# DSC28034 register map
Vendor: Beijing Haawking Technology Co.,Ltd.; File version: 1.0
Registers are 32-bit, read-write, reset 0x0 unless marked. A register's access mark holds for its fields unless they carry their own. Offsets are from the block's base; [hi:lo] are bit positions; {n}, {i} and the like mark numbered series; 'fields as' and 'values as' point back to an identical list.

## GPIOHS — High-speed GPIO
Base 0x38001000
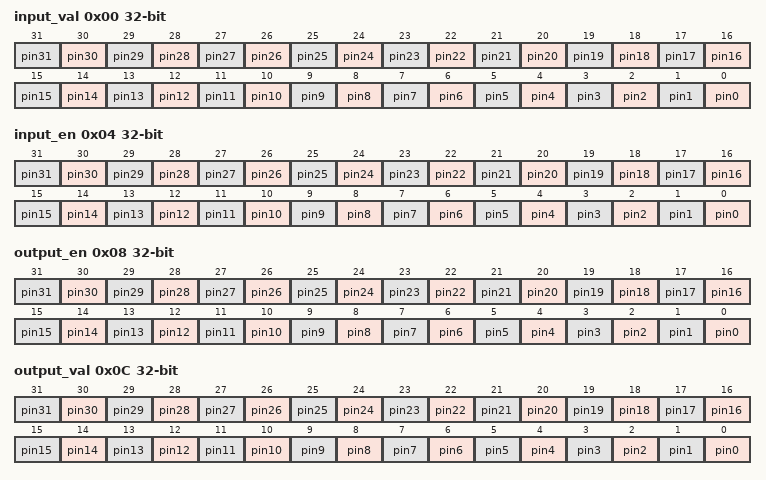
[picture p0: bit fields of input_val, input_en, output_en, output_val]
0x00 input_val — Input Value Register
  [n] pin{n} (n=0..31)
0x04 input_en — Pin Input Enable Register
  [n] pin{n} (n=0..31)
0x08 output_en — Pin Output Enable Register
  [n] pin{n} (n=0..31)
0x0C output_val — Output Value Register
  [n] pin{n} (n=0..31)
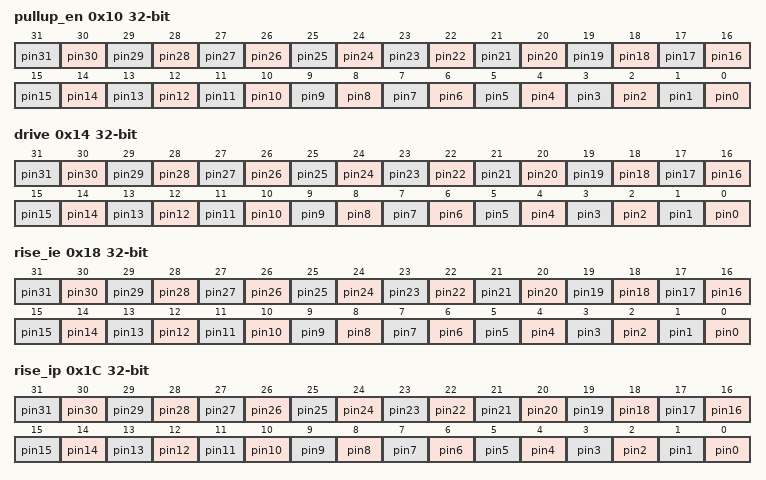
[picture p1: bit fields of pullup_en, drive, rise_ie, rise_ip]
0x10 pullup_en — Internal Pull-Up Enable Register
  [n] pin{n} (n=0..31)
0x14 drive — Drive Strength Register
  [n] pin{n} (n=0..31)
0x18 rise_ie — Rise Interrupt Enable Register
  [n] pin{n} (n=0..31)
0x1C rise_ip — Rise Interrupt Pending Register
  [n] pin{n} (n=0..31)
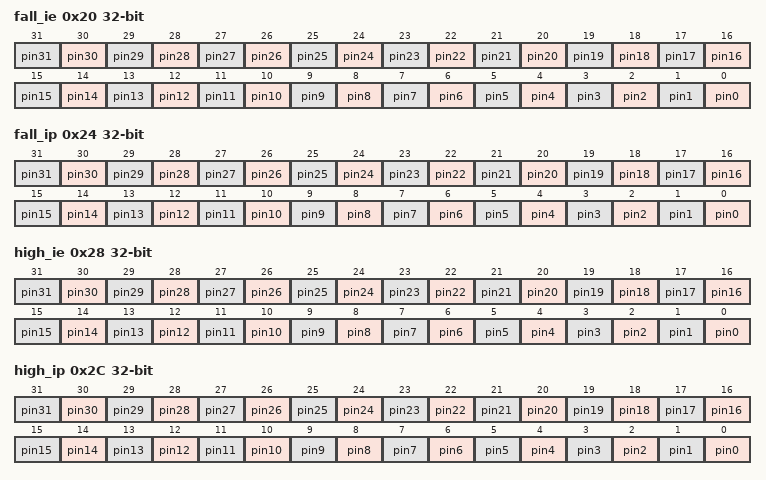
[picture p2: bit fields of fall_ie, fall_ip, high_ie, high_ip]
0x20 fall_ie — Fall Interrupt Enable Register
  [n] pin{n} (n=0..31)
0x24 fall_ip — Fall Interrupt Pending Register
  [n] pin{n} (n=0..31)
0x28 high_ie — High Interrupt Enable Register
  [n] pin{n} (n=0..31)
0x2C high_ip — High Interrupt Pending Register
  [n] pin{n} (n=0..31)
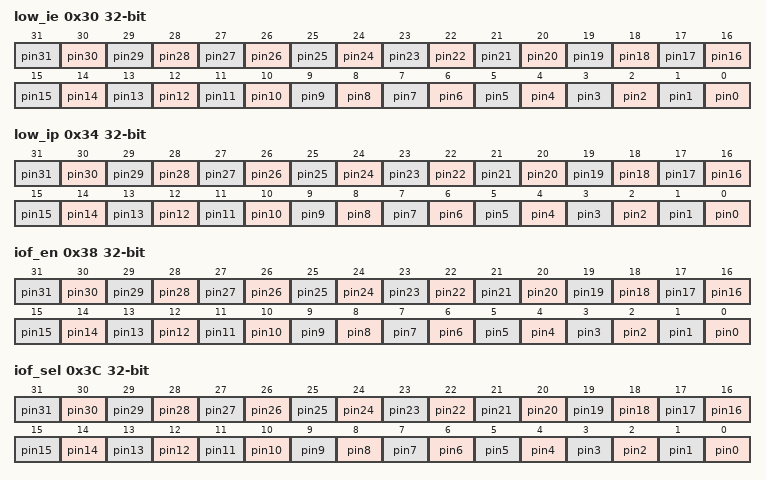
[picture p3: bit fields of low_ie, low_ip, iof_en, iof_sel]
0x30 low_ie — Low Interrupt Enable Register
  [n] pin{n} (n=0..31)
0x34 low_ip — Low Interrupt Pending Register
  [n] pin{n} (n=0..31)
0x38 iof_en — HW I/O Function Enable Register
  [n] pin{n} (n=0..31)
0x3C iof_sel — HW I/O Function Select Register
  [n] pin{n} (n=0..31)
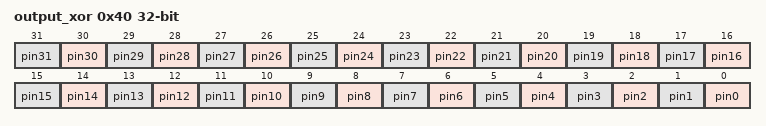
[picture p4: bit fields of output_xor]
0x40 output_xor — Output XOR (invert) Register
  [n] pin{n} (n=0..31)

## KPU — Neural Network Accelerator
Base 0x40800000
0x00 layer_argument_fifo 64-bit (reset mask 0xFFFFFFFF) — Layer arguments FIFO: each layer is defined by writing 12 successive argument values to this register
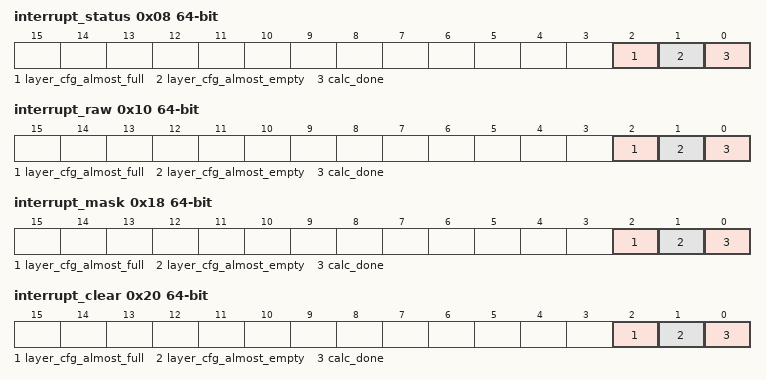
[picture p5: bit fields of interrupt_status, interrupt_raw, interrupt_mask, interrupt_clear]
0x08 interrupt_status 64-bit
  [2] layer_cfg_almost_full — Interrupt raised when layer arguments FIFO almost full
  [1] layer_cfg_almost_empty — Interrupt raised when layer arguments FIFO almost empty
  [0] calc_done — Interrupt raised when calculation is done
0x10 interrupt_raw 64-bit
  fields as interrupt_status
0x18 interrupt_mask 64-bit — Interrupt mask: 0 enables the interrupt, 1 masks the interrupt
  fields as interrupt_status
0x20 interrupt_clear 64-bit — Interrupt clear: write 1 to a bit to clear interrupt
  fields as interrupt_status
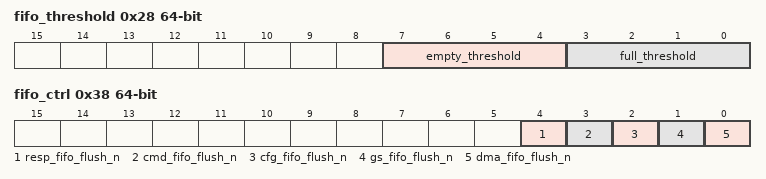
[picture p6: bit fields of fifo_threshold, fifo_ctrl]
0x28 fifo_threshold 64-bit
  [7:4] empty_threshold — FIFO empty threshold
  [3:0] full_threshold — FIFO full threshold
0x30 fifo_data_out 64-bit (reset mask 0xFFFFFFFF) — FIFO data output
0x38 fifo_ctrl 64-bit — FIFO control
  [4] resp_fifo_flush_n — Flush response FIFO
  [3] cmd_fifo_flush_n — Flush command FIFO
  [2] cfg_fifo_flush_n — Flush configuration FIFO
  [1] gs_fifo_flush_n — Flush GS FIFO
  [0] dma_fifo_flush_n — Flush DMA FIFO
0x40 eight_bit_mode 64-bit
  [0] eight_bit_mode — Use 8-bit instead of 16-bit precision if set

## FFT — Fast Fourier Transform Accelerator
Base 0x42000000
0x00 input_fifo 64-bit (reset mask 0xFFFFFFFF) — FFT input data fifo
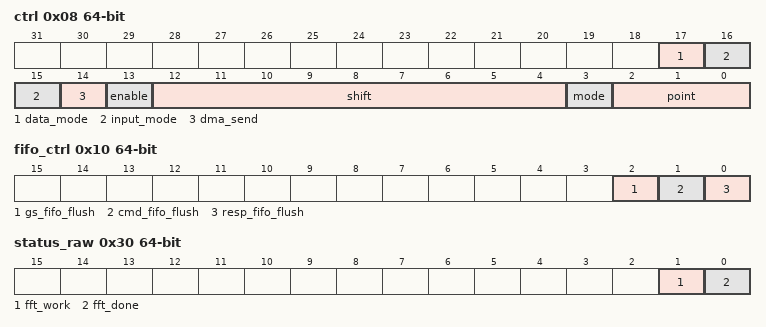
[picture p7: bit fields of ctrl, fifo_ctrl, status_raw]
0x08 ctrl 64-bit — FFT control register
  [17] data_mode — Effective width of input data
    0=width_64 (64 bit effective); 1=width_128 (128 bit effective)
  [16:15] input_mode — Input data arrangement
    0=RIRI (real imaginary interleaved); 1=RRRR (only real part); 2=rrii (First input the real part and then input the imaginary part)
  [14] dma_send — FFT DMA enable
  [13] enable — FFT enable
  [12:4] shift — Corresponding to the nine layer butterfly shift operation, 0x0: does not shift; 0x1: shift 1st layer. ...
  [3] mode — FFT mode
    0=fft (FFT mode); 1=ifft (Inverse FFT mode)
  [2:0] point — FFT calculation data length
    0=p512 (512 point); 1=p256 (256 point); 2=p128 (128 point); 3=p64 (64 point)
0x10 fifo_ctrl 64-bit — FIFO control
  [2] gs_fifo_flush — Output interface memory initialization flag
  [1] cmd_fifo_flush — Command memory initialization flag
  [0] resp_fifo_flush — Response memory initialization flag
0x18 intr_mask 64-bit — interrupt mask
  [0] fft_done
0x20 intr_clear 64-bit — Interrupt clear
  [0] fft_done
0x28 status 64-bit — FFT status register
  [0] fft_done
0x30 status_raw 64-bit — FFT status raw
  [1] fft_work, [0] fft_done
0x38 output_fifo 64-bit (reset mask 0xFFFFFFFF) — FFT output FIFO
